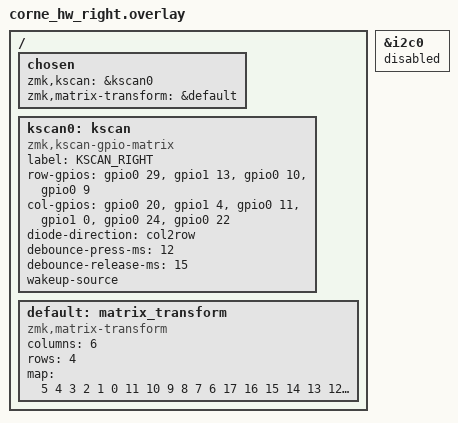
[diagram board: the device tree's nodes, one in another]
/ {
    chosen {
        zmk,kscan = &kscan0;
        zmk,matrix-transform = &default;
    };

    kscan0: kscan {
        compatible = "zmk,kscan-gpio-matrix";
        label = "KSCAN_RIGHT";

        /* Rows: P0.29, P1.13, P0.10, P0.09 */
        row-gpios = <&gpio0 29 (GPIO_ACTIVE_HIGH | GPIO_PULL_DOWN)>,
                    <&gpio1 13 (GPIO_ACTIVE_HIGH | GPIO_PULL_DOWN)>,
                    <&gpio0 10 (GPIO_ACTIVE_HIGH | GPIO_PULL_DOWN)>,
                    <&gpio0 9  (GPIO_ACTIVE_HIGH | GPIO_PULL_DOWN)>;

        /* Cols: P1.06, P1.04, P0.11, P1.00, P0.24, P0.22 */
        col-gpios = <&gpio0 20  GPIO_ACTIVE_HIGH>,
                    <&gpio1 4  GPIO_ACTIVE_HIGH>,
                    <&gpio0 11 GPIO_ACTIVE_HIGH>,
                    <&gpio1 0  GPIO_ACTIVE_HIGH>,
                    <&gpio0 24 GPIO_ACTIVE_HIGH>,
                    <&gpio0 22 GPIO_ACTIVE_HIGH>;

        diode-direction = "col2row";

        /* Debounce (anti-spam) */
        debounce-press-ms = <12>;
        debounce-release-ms = <15>;

        wakeup-source;
    };

    default: matrix_transform {
        compatible = "zmk,matrix-transform";
        columns = <6>;
        rows = <4>;
        map = <
            5 4 3 2 1 0
            11 10 9 8 7 6
            17 16 15 14 13 12
            23 22 21 20 19 18
        >;
    };
};

&i2c0 {
    status = "disabled";
};
